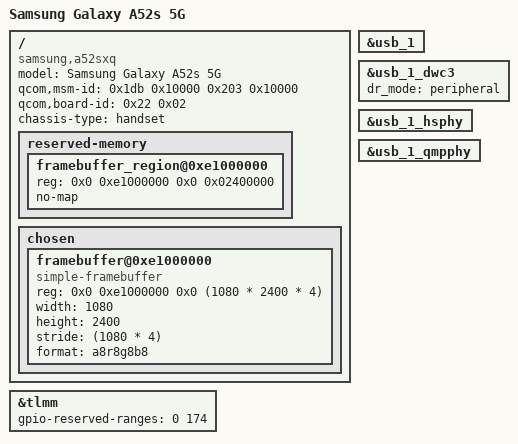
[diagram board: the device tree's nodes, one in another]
// SPDX-License-Identifier: BSD-3-Clause
/*
 * Copyright (c) 2024, Eugene Lepshy <fekz115@gmail.com>
 */

/dts-v1/;

#include <dt-bindings/gpio/gpio.h>
#include <dt-bindings/regulator/qcom,rpmh-regulator.h>

#include "sm7325.dtsi"

/delete-node/ &video_mem;
/delete-node/ &rmtfs_mem;

/ {
        model = "Samsung Galaxy A52s 5G";
        compatible = "samsung,a52sxq", "qcom,sm7325";
        qcom,msm-id = <0x1db 0x10000 0x203 0x10000>;
        qcom,board-id = <0x22 0x02>;
        chassis-type = "handset";

        reserved-memory {
                #address-cells = <2>;
                #size-cells = <2>;
                ranges;

                framebuffer_region@0xe1000000 {
                        reg = <0x0 0xe1000000 0x0 0x02400000>;
                        no-map;
                };
        };

        chosen {
                #address-cells = <2>;
                #size-cells = <2>;
                ranges;

                framebuffer@0xe1000000 {
                        compatible = "simple-framebuffer";
                        reg = <0x0 0xe1000000 0x0 (1080 * 2400 * 4)>;
                        width = <1080>;
                        height = <2400>;
                        stride = <(1080 * 4)>;
                        format = "a8r8g8b8";
                };
        };
};

&tlmm {
    // Reserve all
	gpio-reserved-ranges = <0 174>;
};

&usb_1 {
	status = "okay";
};

&usb_1_dwc3 {
	dr_mode = "peripheral";
};

&usb_1_hsphy {
	status = "okay";
	// vdd-supply = <&vreg_l4a>;
	// vdda-pll-supply = <&vreg_l11a>;
	// vdda-phy-dpdm-supply = <&vreg_l17a>;
};

&usb_1_qmpphy {
	status = "okay";
	// vdda-phy-supply = <&vreg_l4a>;
	// vdda-pll-supply = <&vreg_l3c>;
};
